# ATSAML22J17A register map
Vendor: Microchip Technology; Series: SAML22; File version: 0
CPU: CM0+ r0p0, little endian, MPU, no FPU, VTOR, 2 interrupt priority bits, 26 interrupts
Registers are 32-bit, read-write, reset 0x0 unless marked. A register's access mark holds for its fields unless they carry their own. Offsets are from the block's base; [hi:lo] are bit positions; {n}, {i} and the like mark numbered series; 'fields as' and 'values as' point back to an identical list.

## TRNG — True Random Generator
Base 0x42004400
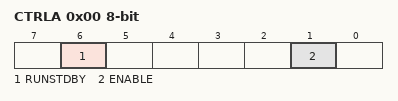
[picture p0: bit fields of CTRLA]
0x00 CTRLA 8-bit — Control A
  [6] RUNSTDBY — Run in Standby
  [1] ENABLE
0x04 EVCTRL 8-bit — Event Control
  [0] DATARDYEO — Data Ready Event Output
0x08 INTENCLR 8-bit write-1-clears — Interrupt Enable Clear
  [0] DATARDY — Data Ready Interrupt Enable
0x09 INTENSET 8-bit write-1-sets — Interrupt Enable Set
  [0] DATARDY — Data Ready Interrupt Enable
0x0A INTFLAG 8-bit write-1-clears — Interrupt Flag Status and Clear
  [0] DATARDY — Data Ready Interrupt Flag
0x20 DATA ro — Output Data

## WDT — Watchdog Timer
Base 0x40002000
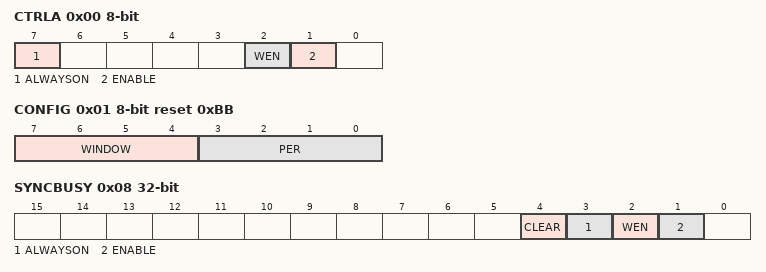
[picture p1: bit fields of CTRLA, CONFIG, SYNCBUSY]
0x00 CTRLA 8-bit — Control
  [7] ALWAYSON
  [2] WEN — Watchdog Timer Window Mode Enable
  [1] ENABLE
0x01 CONFIG 8-bit reset 0xBB — Configuration
  [7:4] WINDOW — Window Mode Time-Out Period
    0=CYC8 (8 clock cycles); 1=CYC16 (16 clock cycles); 2=CYC32 (32 clock cycles); 3=CYC64 (64 clock cycles); 4=CYC128 (128 clock cycles); 5=CYC256 (256 clock cycles); 6=CYC512 (512 clock cycles); 7=CYC1024 (1024 clock cycles); 8=CYC2048 (2048 clock cycles); 9=CYC4096 (4096 clock cycles); 10=CYC8192 (8192 clock cycles); 11=CYC16384 (16384 clock cycles)
  [3:0] PER — Time-Out Period
    values as WINDOW
0x02 EWCTRL 8-bit reset 0xB — Early Warning Interrupt Control
  [3:0] EWOFFSET — Early Warning Interrupt Time Offset
    values as CONFIG.WINDOW
0x04 INTENCLR 8-bit write-1-clears — Interrupt Enable Clear
  [0] EW — Early Warning Interrupt Enable
0x05 INTENSET 8-bit write-1-sets — Interrupt Enable Set
  [0] EW — Early Warning Interrupt Enable
0x06 INTFLAG 8-bit write-1-clears — Interrupt Flag Status and Clear
  [0] EW — Early Warning
0x08 SYNCBUSY ro — Synchronization Busy
  [4] CLEAR — Clear Busy
  [3] ALWAYSON — Always-On Busy
  [2] WEN — Window Enable Busy
  [1] ENABLE — Enable Busy
0x0C CLEAR 8-bit wo
  [7:0] CLEAR — Watchdog Clear
    165=KEY (Clear Key)

## MPU — Memory Protection Unit
Base 0xE000ED90
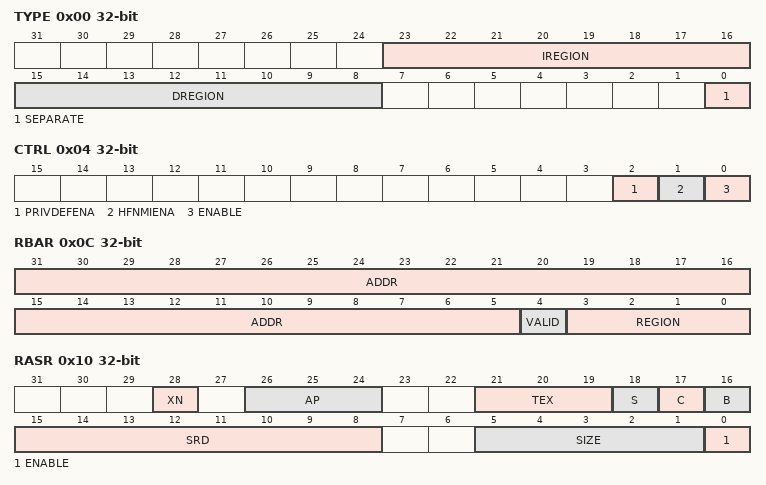
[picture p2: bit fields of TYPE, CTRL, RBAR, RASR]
0x00 TYPE ro — MPU Type Register
  [23:16] IREGION — Number of Instruction Regions
  [15:8] DREGION — Number of Data Regions
  [0] SEPARATE — Separate instruction and Data Memory MapsRegions
0x04 CTRL — MPU Control Register
  [2] PRIVDEFENA — Enables privileged software access to default memory map
  [1] HFNMIENA — Enable Hard Fault and NMI handlers
  [0] ENABLE — MPU Enable
0x08 RNR — MPU Region Number Register
  [7:0] REGION — Region referenced by RBAR and RASR
0x0C RBAR — MPU Region Base Address Register
  [31:5] ADDR — Region base address
  [4] VALID — Region number valid
  [3:0] REGION — Region number
0x10 RASR — MPU Region Attribute and Size Register
  [28] XN — Execute Never Attribute
  [26:24] AP — Access Permission
  [21:19] TEX — TEX bit
  [18] S — Shareable bit
  [17] C — Cacheable bit
  [16] B — Bufferable bit
  [15:8] SRD — Sub-region disable
  [5:1] SIZE — Region Size
  [0] ENABLE — Region Enable

## NVIC — Nested Vectored Interrupt Controller
Base 0xE000E100
0x00 ISER — Interrupt Set Enable Register
  [25:0] SETENA — Interrupt set enable bits
0x80 ICER — Interrupt Clear Enable Register
  [25:0] CLRENA — Interrupt clear-enable bits
0x100 ISPR — Interrupt Set Pending Register
  [25:0] SETPEND — Interrupt set-pending bits
0x180 ICPR — Interrupt Clear Pending Register
  [25:0] CLRPEND — Interrupt clear-pending bits
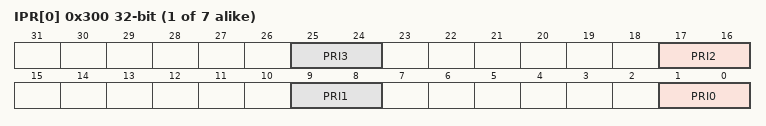
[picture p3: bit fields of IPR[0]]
{0x300+4i} IPR[{i}] (i=0..6) — Interrupt Priority Register n
  [8n+1:8n] PRI{n} (n=0..3) — Priority of interrupt n

## SysTick — System timer
Base 0xE000E010
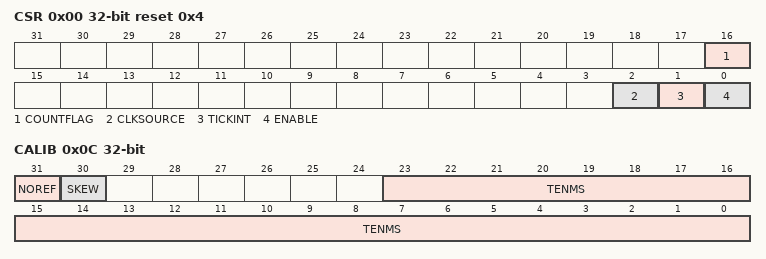
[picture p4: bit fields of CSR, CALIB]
0x00 CSR reset 0x4 — SysTick Control and Status Register
  [16] COUNTFLAG — Timer counted to 0 since last read of register
  [2] CLKSOURCE — Clock Source 0=external, 1=processor
    0=External clock; 1=Processor clock
  [1] TICKINT — SysTick Exception Request Enable
    0=Counting down to 0 does not assert the SysTick exception request; 1=Counting down to 0 asserts the SysTick exception request
  [0] ENABLE — SysTick Counter Enable
    0=Counter disabled; 1=Counter enabled
0x04 RVR — SysTick Reload Value Register
  [23:0] RELOAD — Value to load into the SysTick Current Value Register when the counter reaches 0
0x08 CVR — SysTick Current Value Register
  [23:0] CURRENT — Current value at the time the register is accessed
0x0C CALIB ro — SysTick Calibration Value Register
  [31] NOREF — No Separate Reference Clock
    0=The reference clock is provided; 1=The reference clock is not provided
  [30] SKEW — TENMS is rounded from non-integer ratio
    0=10ms calibration value is exact; 1=10ms calibration value is inexact, because of the clock frequency
  [23:0] TENMS — Reload value to use for 10ms timing

## SystemControl — System Control Registers
Base 0xE000E000
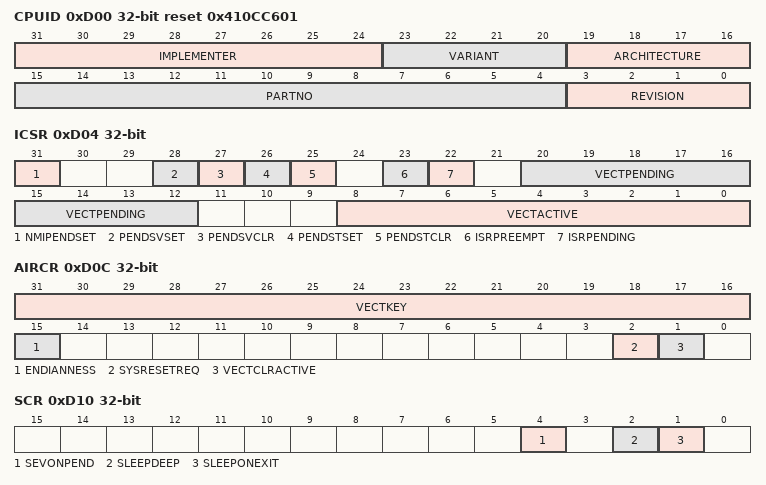
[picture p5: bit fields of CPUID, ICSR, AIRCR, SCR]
0xD00 CPUID ro reset 0x410CC601 — CPUID Base Register
  [31:24] IMPLEMENTER — Implementer code, ARM=0x41
  [23:20] VARIANT — Major revision number
  [19:16] ARCHITECTURE — Processor Architecture, 0xC=ARMv6-M
  [15:4] PARTNO — Processor Part Number, 0xC60=Cortex-M0+
  [3:0] REVISION — Minor revision number
0xD04 ICSR — Interrupt Control and State Register
  [31] NMIPENDSET — NMI set-pending bit
    0=Write: no effect; read: NMI exception is not pending; 1=Write: changes NMI exception state to pending; read: NMI exception is pending
  [28] PENDSVSET — PendSV set-pending bit
    0=Write: no effect; read: PendSV exception is not pending; 1=Write: changes PendSV exception state to pending; read: PendSV exception is pending
  [27] PENDSVCLR — PendSV clear-pending bit
    0=No effect; 1=Removes the pending state from the PendSV exception
  [26] PENDSTSET — SysTick exception set-pending bit
    0=Write: no effect; read: SysTick exception is not pending; 1=Write: changes SysTick exception state to pending; read: SysTick exception is pending
  [25] PENDSTCLR — SysTick exception clear-pending bit
    0=No effect; 1=Removes the pending state from the SysTick exception
  [23] ISRPREEMPT — Debug: Pending exception serviced on exit from debug halt
  [22] ISRPENDING — Debug: NVIC interrupt pending
  [20:12] VECTPENDING — Exception number of the highest priority pending enabled exception
  [8:0] VECTACTIVE — Debug: Exception number of currently executing exception, or 0 if thread mode
0xD08 VTOR — Vector Table Offset Register
  [31:7] TBLOFF — Vector table base offset
0xD0C AIRCR — Application Interrupt and Reset Control Register
  [31:16] VECTKEY — Register key (0x05FA)
  [15] ENDIANNESS — Data Endianness, 0=little, 1=big
    0=Little-endian; 1=Big-endian
  [2] SYSRESETREQ — System Reset Request
    0=No system reset request; 1=Asserts a signal to the outer system that requests a reset
  [1] VECTCLRACTIVE — Debug: Clear state information
0xD10 SCR — System Control Register
  [4] SEVONPEND — Send Event on Pending bit
    0=Only enabled interrupts or events can wakeup the processor, disabled interrupts are excluded; 1=Enabled events and all interrupts, including disabled interrupts, can wakeup the processor
  [2] SLEEPDEEP — Uses Deep Sleep as low power mode
    0=Sleep; 1=Deep sleep
  [1] SLEEPONEXIT — Sleep-On-Exit when exiting Handler mode
    0=O not sleep when returning to Thread mode; 1=Enter sleep, or deep sleep, on return from an ISR
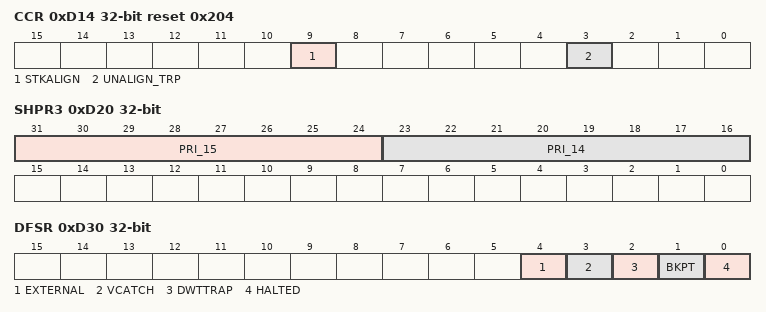
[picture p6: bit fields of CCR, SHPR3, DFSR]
0xD14 CCR ro reset 0x204 — Configuration and Control Register
  [9] STKALIGN — Stack 8-byte aligned on exception entry
    0=4-byte aligned; 1=8-byte aligned
  [3] UNALIGN_TRP — Unaligned accesses generates a Hard Fault
    0=Do not trap unaligned halfword and word accesses; 1=Trap unaligned halfword and word accesses
0xD1C SHPR2 — System Handler Priority Register 2
  [31:24] PRI_11 — Priority of system handler 11, SVCall
0xD20 SHPR3 — System Handler Priority Register 3
  [31:24] PRI_15 — Priority of system handler 15, SysTick exception
  [23:16] PRI_14 — Priority of system handler 14, PendSV
0xD24 SHCSR — System Handler Control and State Register
  [15] SVCALLPENDED
0xD30 DFSR — Debug Fault Status Register
  [4] EXTERNAL — EDBGRQ debug event
  [3] VCATCH — Vector catch debug event
  [2] DWTTRAP — DWT debug event
  [1] BKPT — Breakpoint debug event
  [0] HALTED — Halt request debug event active
